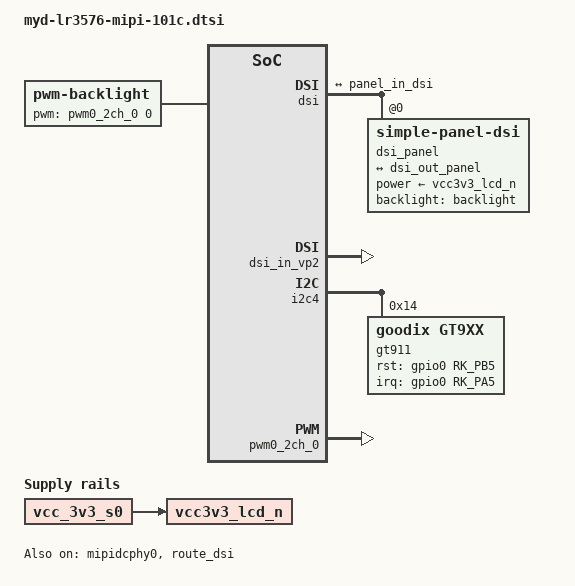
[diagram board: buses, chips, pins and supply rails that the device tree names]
// SPDX-License-Identifier: (GPL-2.0+ OR MIT)
/*
 * Copyright (c) 2024 MYIR Electronics Co., Ltd.
 *
 */

#include <dt-bindings/display/drm_mipi_dsi.h>
#include <dt-bindings/display/rockchip_vop.h>

/ {

	vcc3v3_lcd_n: vcc3v3-lcd0-n {
		compatible = "regulator-fixed";
		regulator-name = "vcc3v3_lcd0_n";
		regulator-boot-on;
		enable-active-high;
		vin-supply = <&vcc_3v3_s0>;
	};

	backlight: backlight {
		compatible = "pwm-backlight";
		pwms = <&pwm0_2ch_0 0 2000 0>;
		brightness-levels = <
			  0  20  20  21  21  22  22  23
			 23  24  24  25  25  26  26  27
			 27  28  28  29  29  30  30  31
			 31  32  32  33  33  34  34  35
			 35  36  36  37  37  38  38  39
			 40  41  42  43  44  45  46  47
			 48  49  50  51  52  53  54  55
			 56  57  58  59  60  61  62  63
			 64  65  66  67  68  69  70  71
			 72  73  74  75  76  77  78  79
			 80  81  82  83  84  85  86  87
			 88  89  90  91  92  93  94  95
			 96  97  98  99 100 101 102 103
			104 105 106 107 108 109 110 111
			112 113 114 115 116 117 118 119
			120 121 122 123 124 125 126 127
			128 129 130 131 132 133 134 135
			136 137 138 139 140 141 142 143
			144 145 146 147 148 149 150 151
			152 153 154 155 156 157 158 159
			160 161 162 163 164 165 166 167
			168 169 170 171 172 173 174 175
			176 177 178 179 180 181 182 183
			184 185 186 187 188 189 190 191
			192 193 194 195 196 197 198 199
			200 201 202 203 204 205 206 207
			208 209 210 211 212 213 214 215
			216 217 218 219 220 221 222 223
			224 225 226 227 228 229 230 231
			232 233 234 235 236 237 238 239
			240 241 242 243 244 245 246 247
			248 249 250 251 252 253 254 255
		>;
		default-brightness-level = <200>;
	};
};

&dsi {
	status = "okay";
	//rockchip,lane-rate = <1000>;
	dsi_panel: panel@0 {
		status = "okay";
		compatible = "simple-panel-dsi";
		reg = <0>;
		backlight = <&backlight>;
		power-supply = <&vcc3v3_lcd_n>;
		reset-delay-ms = <10>;
		enable-delay-ms = <10>;
		prepare-delay-ms = <10>;
		unprepare-delay-ms = <10>;
		disable-delay-ms = <60>;
		width-mm = <68>;
		height-mm = <121>;
		dsi,flags = <(MIPI_DSI_MODE_VIDEO | MIPI_DSI_MODE_VIDEO_BURST |
			      MIPI_DSI_MODE_LPM | MIPI_DSI_MODE_NO_EOT_PACKET)>;
		dsi,format = <MIPI_DSI_FMT_RGB888>;
		dsi,lanes  = <4>;
		panel-init-sequence = [
                        23 00 02 B0 5A
                        23 00 02 B1 00
                        23 00 02 89 01
                        23 00 02 2C 28
                        23 00 02 00 F1
                        05 78 01 11
                        05 14 01 29
                ];

		panel-exit-sequence = [
			05 00 01 28
			05 00 01 10
		];

		disp_timings0: display-timings {
			native-mode = <&dsi_timing0>;
			dsi_timing0: timing0 {
				clock-frequency = <150000000>;  //56hz while use vp2
				hactive = <1200>;
				vactive = <1920>;
				hfront-porch = <80>;
				hsync-len = <1>;
				hback-porch = <60>;
				vfront-porch = <35>;
				vsync-len = <1>;
				vback-porch = <25>;
				hsync-active = <0>;
				vsync-active = <0>;
				de-active = <0>;
				pixelclk-active = <0>;
			};
		};

		ports {
			#address-cells = <1>;
			#size-cells = <0>;

			port@0 {
				reg = <0>;
				panel_in_dsi: endpoint {
					remote-endpoint = <&dsi_out_panel>;
				};
			};
		};
	};

	ports {
		#address-cells = <1>;
		#size-cells = <0>;

		port@1 {
			reg = <1>;
			dsi_out_panel: endpoint {
				remote-endpoint = <&panel_in_dsi>;
			};
		};
	};
};

&dsi_in_vp2 {
	status = "okay";
};

&i2c4 {
	status = "okay";

	gt911: gt911@14 {
		status = "okay";
		compatible = "goodix,gt9xx";
		reg = <0x14>;
		pinctrl-names = "default";
		pinctrl-0 = <&gt9xx_touch_gpio>;
		interrupt-parent = <&gpio0>;
		interrupts = <RK_PA5 IRQ_TYPE_EDGE_FALLING>;
		goodix,rst-gpio = <&gpio0 RK_PB5 GPIO_ACTIVE_HIGH>;
		goodix,irq-gpio = <&gpio0 RK_PA5 IRQ_TYPE_LEVEL_LOW>;
		read-tp-thread = <1>;
		flip-x = <0>;
		flip-y = <0>;

		touchscreen-size-x = <1200>;
		touchscreen-size-y = <1920>;

		goodix,cfg-group0 = [
			FA B0 04 80 07 05 35 00 01 08
			28 08 5A 3C 03 05 00 00 00 00
			11 11 00 18 1A 1E 14 8C 2E 0E
			71 73 B2 04 00 00 00 D9 02 1D
			00 01 00 00 00 00 00 00 00 00
			00 50 A0 94 D5 02 07 00 00 04
			95 55 00 89 62 00 80 71 00 78
			82 00 72 95 00 72 00 00 00 00
			00 00 00 00 00 00 00 00 00 00
			00 00 00 00 00 00 00 00 00 00
			00 00 00 00 00 00 00 00 00 00
			00 00 1C 1A 18 16 14 12 10 0E
			0C 0A 08 06 04 02 00 00 00 00
			00 00 00 00 00 00 00 00 00 00
			00 00 00 02 04 06 08 0A 0C 0F
			10 12 13 14 16 2A 29 28 26 24
			22 21 20 1F 1E 1D 1C 18 00 00
			00 00 00 00 00 00 00 00 00 00
			00 00 00 00 1A 01
		];
	};
};

/*
 * mipidcphy0 needs to be enabled
 * when dsi is enabled
 */
&mipidcphy0 {
	status = "okay";
};

&pinctrl {
	touch {
		gt9xx_touch_gpio: gt9xx-touch-gpio {
			rockchip,pins =
				<0 RK_PB5 RK_FUNC_GPIO &pcfg_pull_up>,
				<0 RK_PA5 RK_FUNC_GPIO &pcfg_pull_none>;
		};
	};
};

&pwm0_2ch_0 {
	status = "okay";
};

&route_dsi {
	status = "okay";
	connect = <&vp2_out_dsi>;
};
